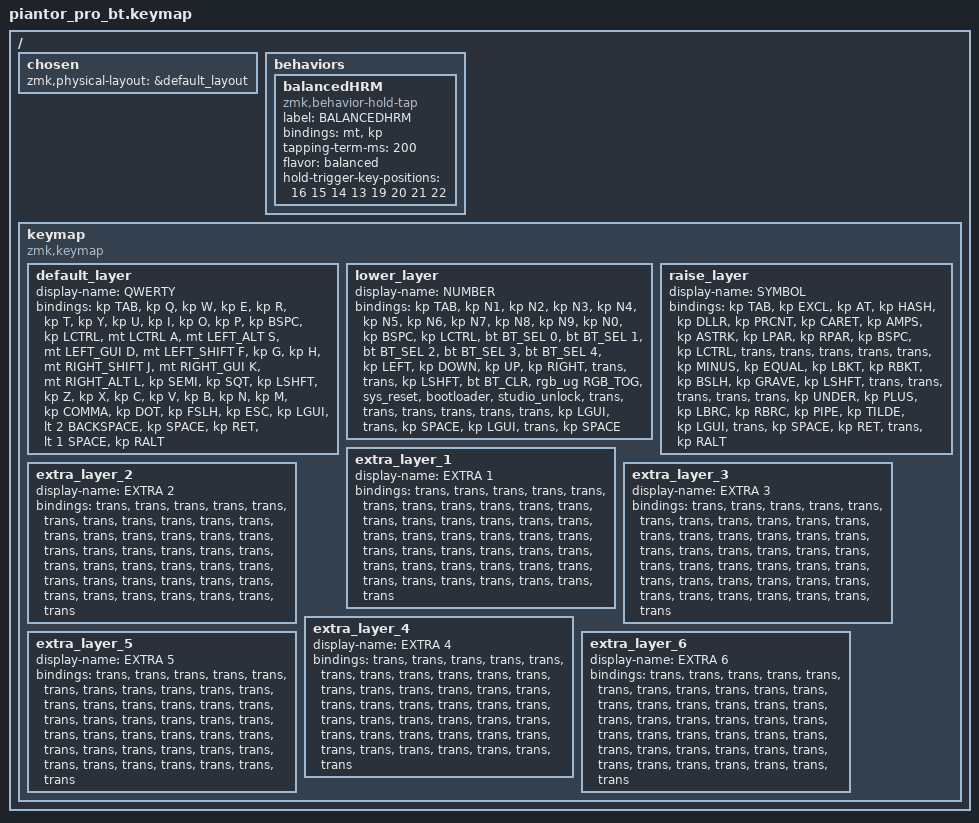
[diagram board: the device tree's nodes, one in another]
/*
 * Copyright (c) 2020 The ZMK Contributors
 *
 * SPDX-License-Identifier: MIT
 */

#include <behaviors.dtsi>
#include <dt-bindings/zmk/bt.h>
#include <dt-bindings/zmk/keys.h>
#include <dt-bindings/zmk/rgb.h>

/ {
    chosen { zmk,physical-layout = &default_layout; };
};

/ {
    behaviors {
        balancedHRM: balancedHRM {
            compatible = "zmk,behavior-hold-tap";
            label = "BALANCEDHRM";
            bindings = <&mt>, <&kp>;

            #binding-cells = <2>;
            tapping-term-ms = <200>;
            flavor = "balanced";
            hold-trigger-key-positions = <16 15 14 13 19 20 21 22>;
        };
    };

    keymap {
        compatible = "zmk,keymap";

        default_layer {
            display-name = "QWERTY";

            // --------------------------------------------------------------------------------
            // |  TAB |  Q  |  W  |  E  |  R  |  T  |  Y  |  U   |  I  |  O  |  P  | BSPC |
            // | CTRL |  A  |  S  |  D  |  F  |  G  |  H  |  J   |  K  |  L  |  ;  |  '   |
            // | SHFT |  Z  |  X  |  C  |  V  |  B  |  N  |  M   |  ,  |  .  |  /  | ESC  |
            //                    | GUI | LWR | SPC | ENT | RSE  | ALT |

            bindings = <
&kp TAB  &kp Q  &kp W  &kp E  &kp R  &kp T  &kp Y  &kp U  &kp I  &kp O  &kp P  &kp BSPC  &kp LCTRL  &mt LCTRL A  &mt LEFT_ALT S  &mt LEFT_GUI D  &mt LEFT_SHIFT F  &kp G  &kp H  &mt RIGHT_SHIFT J  &mt RIGHT_GUI K  &mt RIGHT_ALT L  &kp SEMI  &kp SQT  &kp LSHFT  &kp Z  &kp X  &kp C  &kp V  &kp B  &kp N  &kp M  &kp COMMA  &kp DOT  &kp FSLH  &kp ESC  &kp LGUI  &lt 2 BACKSPACE  &kp SPACE  &kp RET  &lt 1 SPACE  &kp RALT
            >;
        };

        lower_layer {
            display-name = "NUMBER";

            // -----------------------------------------------------------------------------------------
            // |  TAB |  1  |  2  |  3  |  4  |  5    |  6  |  7  |  8  |  9  |  0  | BSPC |
            // | CTRL | BT1 | BT2 | BT3 | BT4 | BT5   | LFT | DWN |  UP | RGT |     |      |
            // | SHFT | BTCR| RGB | RST | BOOT| Unlock|     |     |     |     |     |      |
            //                    | GUI |     | SPC   | ENT |     | ALT |

            bindings = <
&kp TAB  &kp N1  &kp N2  &kp N3  &kp N4  &kp N5  &kp N6  &kp N7  &kp N8  &kp N9  &kp N0  &kp BSPC  &kp LCTRL  &bt BT_SEL 0  &bt BT_SEL 1  &bt BT_SEL 2  &bt BT_SEL 3  &bt BT_SEL 4  &kp LEFT  &kp DOWN  &kp UP  &kp RIGHT  &trans  &trans  &kp LSHFT  &bt BT_CLR  &rgb_ug RGB_TOG  &sys_reset  &bootloader  &studio_unlock  &trans  &trans  &trans  &trans  &trans  &trans  &kp LGUI  &trans  &kp SPACE  &kp LGUI  &trans  &kp SPACE
            >;
        };

        raise_layer {
            display-name = "SYMBOL";

            // -----------------------------------------------------------------------------------------
            // |  TAB |  !  |  @  |  #  |  $  |  %  |  ^  |  &  |  *  |  (  |  )  | BSPC |
            // | CTRL |     |     |     |     |     |  -  |  =  |  [  |  ]  |  \  |  `   |
            // | SHFT |     |     |     |     |     |  _  |  +  |  {  |  }  | "|" |  ~   |
            //                    | GUI |     | SPC | ENT |     | ALT |

            bindings = <
&kp TAB  &kp EXCL  &kp AT  &kp HASH  &kp DLLR  &kp PRCNT  &kp CARET  &kp AMPS  &kp ASTRK  &kp LPAR  &kp RPAR  &kp BSPC  &kp LCTRL  &trans  &trans  &trans  &trans  &trans  &kp MINUS  &kp EQUAL  &kp LBKT  &kp RBKT  &kp BSLH  &kp GRAVE  &kp LSHFT  &trans  &trans  &trans  &trans  &trans  &kp UNDER  &kp PLUS  &kp LBRC  &kp RBRC  &kp PIPE  &kp TILDE  &kp LGUI  &trans  &kp SPACE  &kp RET  &trans  &kp RALT
            >;
        };

        extra_layer_1 {
            display-name = "EXTRA 1";
            bindings = <
&trans  &trans  &trans  &trans  &trans  &trans  &trans  &trans  &trans  &trans  &trans  &trans  &trans  &trans  &trans  &trans  &trans  &trans  &trans  &trans  &trans  &trans  &trans  &trans  &trans  &trans  &trans  &trans  &trans  &trans  &trans  &trans  &trans  &trans  &trans  &trans  &trans  &trans  &trans  &trans  &trans  &trans
            >;
        };

        extra_layer_2 {
            display-name = "EXTRA 2";
            bindings = <
&trans  &trans  &trans  &trans  &trans  &trans  &trans  &trans  &trans  &trans  &trans  &trans  &trans  &trans  &trans  &trans  &trans  &trans  &trans  &trans  &trans  &trans  &trans  &trans  &trans  &trans  &trans  &trans  &trans  &trans  &trans  &trans  &trans  &trans  &trans  &trans  &trans  &trans  &trans  &trans  &trans  &trans
            >;
        };

        extra_layer_3 {
            display-name = "EXTRA 3";
            bindings = <
&trans  &trans  &trans  &trans  &trans  &trans  &trans  &trans  &trans  &trans  &trans  &trans  &trans  &trans  &trans  &trans  &trans  &trans  &trans  &trans  &trans  &trans  &trans  &trans  &trans  &trans  &trans  &trans  &trans  &trans  &trans  &trans  &trans  &trans  &trans  &trans  &trans  &trans  &trans  &trans  &trans  &trans
            >;
        };

        extra_layer_4 {
            display-name = "EXTRA 4";
            bindings = <
&trans  &trans  &trans  &trans  &trans  &trans  &trans  &trans  &trans  &trans  &trans  &trans  &trans  &trans  &trans  &trans  &trans  &trans  &trans  &trans  &trans  &trans  &trans  &trans  &trans  &trans  &trans  &trans  &trans  &trans  &trans  &trans  &trans  &trans  &trans  &trans  &trans  &trans  &trans  &trans  &trans  &trans
            >;
        };

        extra_layer_5 {
            display-name = "EXTRA 5";
            bindings = <
&trans  &trans  &trans  &trans  &trans  &trans  &trans  &trans  &trans  &trans  &trans  &trans  &trans  &trans  &trans  &trans  &trans  &trans  &trans  &trans  &trans  &trans  &trans  &trans  &trans  &trans  &trans  &trans  &trans  &trans  &trans  &trans  &trans  &trans  &trans  &trans  &trans  &trans  &trans  &trans  &trans  &trans
            >;
        };

        extra_layer_6 {
            display-name = "EXTRA 6";
            bindings = <
&trans  &trans  &trans  &trans  &trans  &trans  &trans  &trans  &trans  &trans  &trans  &trans  &trans  &trans  &trans  &trans  &trans  &trans  &trans  &trans  &trans  &trans  &trans  &trans  &trans  &trans  &trans  &trans  &trans  &trans  &trans  &trans  &trans  &trans  &trans  &trans  &trans  &trans  &trans  &trans  &trans  &trans
            >;
        };
    };
};
